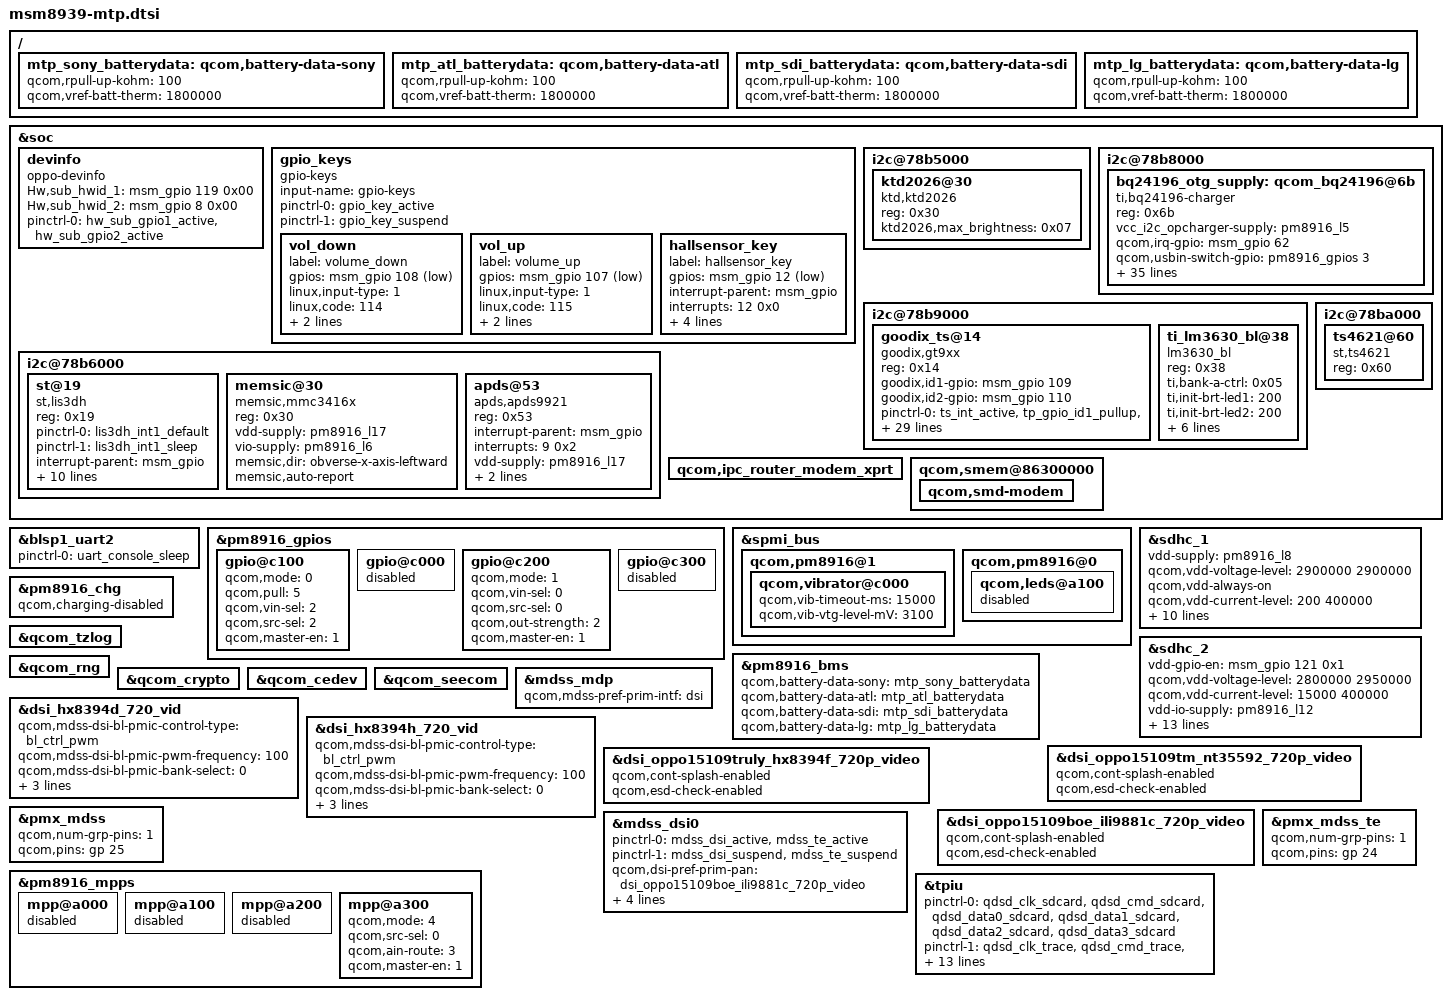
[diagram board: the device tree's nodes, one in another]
/* Copyright (c) 2014-2015, The Linux Foundation. All rights reserved.
 *
 * This program is free software; you can redistribute it and/or modify
 * it under the terms of the GNU General Public License version 2 and
 * only version 2 as published by the Free Software Foundation.
 *
 * This program is distributed in the hope that it will be useful,
 * but WITHOUT ANY WARRANTY; without even the implied warranty of
 * MERCHANTABILITY or FITNESS FOR A PARTICULAR PURPOSE.  See the
 * GNU General Public License for more details.
 */

#include "msm8939-audio-internal_codec.dtsi"
#include "msm8939-camera-sensor-mtp.dtsi"
#include "msm8939-common.dtsi"
#include "msm8939-pinctrl.dtsi"
#include "msm8939-regulator.dtsi"
#include "msm-pm8916.dtsi"
#include "dsi-panel-hx8394d-720p-video.dtsi"
#include "dsi-panel-hx8394h-720p-video.dtsi"
#include "dsi-panel-oppo15109tm-nt35592-720p-video.dtsi"
#include "dsi-panel-oppo15109truly-hx8394f-720p-video.dtsi"
#include "dsi-panel-oppo15109boe-ili9881c-720p-video.dtsi"

&soc {
	devinfo {
		compatible = "oppo-devinfo";
		Hw,sub_hwid_1 = <&msm_gpio 119 0x00>;
		Hw,sub_hwid_2 = <&msm_gpio 8 0x00>;
		pinctrl-names = "default";
		pinctrl-0 = <&hw_sub_gpio1_active &hw_sub_gpio2_active>;
	};

	gpio_keys {
		compatible = "gpio-keys";
		input-name = "gpio-keys";
		pinctrl-names = "tlmm_gpio_key_active", "tlmm_gpio_key_suspend";
		pinctrl-0 = <&gpio_key_active>;
		pinctrl-1 = <&gpio_key_suspend>;

		vol_down {
			label = "volume_down";
			gpios = <&msm_gpio 108 0x1>;
			linux,input-type = <1>;
			linux,code = <114>;
			gpio-key,wakeup;
			debounce-interval = <15>;
		};

		vol_up {
			label = "volume_up";
			gpios = <&msm_gpio 107 0x1>;
			linux,input-type = <1>;
			linux,code = <115>;
			gpio-key,wakeup;
			debounce-interval = <15>;
		};

		hallsensor_key {
			label = "hallsensor_key";
			gpios = <&msm_gpio 12 1>;
			interrupt-parent = <&msm_gpio>;
			interrupts = <12 0x0>;
			linux,input-type = <5>;
			linux,code = <0>;
			gpio-key,wakeup;
			debounce-interval = <150>;
		};
	};

	i2c@78b5000 { /* BLSP1 QUP1 */
		ktd2026@30 {
			status = "okay";
			compatible = "ktd,ktd2026";
			reg = <0x30>;
			ktd2026,max_brightness = <0x07>;
		};
	};

	i2c@78b6000 { /* BLSP1 QUP2 */
		st@19 { /* Accelerometer sensor */
			compatible = "st,lis3dh";
			reg = <0x19>;
			pinctrl-names = "lis3dh_default", "lis3dh_sleep";
			pinctrl-0 = <&lis3dh_int1_default>;
			pinctrl-1 = <&lis3dh_int1_sleep>;
			interrupt-parent = <&msm_gpio>;
			vdd-supply = <&pm8916_l17>;
			vddio-supply = <&pm8916_l6>;
			st,min-interval = <5>;
			st,init-interval = <200>;
			st,axis-map-x = <0>;
			st,axis-map-y = <1>;
			st,axis-map-z = <2>;
			st,g-range = <2>;
			st,negate-x;
			st,negate-z;
		};

		memsic@30 { /* Magnetic field sensor */
			compatible = "memsic,mmc3416x";
			reg = <0x30>;
			vdd-supply = <&pm8916_l17>;
			vio-supply = <&pm8916_l6>;
			memsic,dir = "obverse-x-axis-leftward";
			memsic,auto-report;
		};

		apds@53 { /* Ambient light and proximity sensor */
			compatible = "apds,apds9921";
			reg = <0x53>;
			interrupt-parent = <&msm_gpio>;
			interrupts = <9 0x2>;
			vdd-supply = <&pm8916_l17>;
			vio-supply = <&pm8916_l6>;
			apds,irq-gpio = <&msm_gpio 9 0x02>;
		};
	};

	i2c@78b8000 { /* BLSP1 QUP4 */
		bq24196_otg_supply: qcom_bq24196@6b {
			compatible = "ti,bq24196-charger";
			reg = <0x6b>;
			vcc_i2c_opcharger-supply = <&pm8916_l5>;

			qcom,irq-gpio = <&msm_gpio 62 0x00>;
			qcom,usbin-switch-gpio = <&pm8916_gpios 3 0>;

			qcom,disable-apsd;
			qcom,using-pmic-therm;
			qcom,charger-inhibit-disabled;
			qcom,bms-psy-name = "bms";
			qcom,chg-vadc = <&pm8916_vadc>;
			qcom,chg-adc_tm = <&pm8916_adc_tm>;

			qcom,iterm-ma = <130>;
			qcom,recharge-mv = <200>;
			qcom,fast-charger-project-sign= <0>;
			qcom,fastchg-current-max-ma = <1500>;
			qcom,input-current-max-ma = <1500>;
			qcom,float-voltage-mv = <4320>;

			qcom,hot_bat_decidegc = <530>;
			qcom,temp_hot_vfloat_mv = <4100>;
			qcom,temp_hot_fastchg_current_ma = <535>;

			qcom,warm_bat_decidegc = <450>;
			qcom,temp_warm_vfloat_mv = <4320>;
			qcom,temp_warm_fastchg_current_ma = <1420>;

			qcom,pre_normal_bat_decidegc = <220>;
			qcom,temp_pre_normal_vfloat_mv = <4320>;
			qcom,temp_pre_normal_fastchg_current_ma = <1120>;

			qcom,pre_cool_bat_decidegc = <120>;
			qcom,temp_pre_cool_vfloat_mv = <4320>;
			qcom,temp_pre_cool_fastchg_current_ma = <535>;

			qcom,pre_cool1_bat_decidegc = <50>;
			qcom,temp_pre_cool1_vfloat_mv = <4320>;
			qcom,temp_pre_cool1_fastchg_current_ma = <300>;

			qcom,cool_bat_decidegc = <0>;
			qcom,temp_cool_vfloat_mv = <4000>;
			qcom,temp_cool_fastchg_current_ma = <256>;

			qcom,cold_bat_decidegc = <30>;
			qcom,bat_present_decidegc = <200>;
			qcom,non_standard_vfloat_mv = <4000>;
			qcom,non_standard_fastchg_current_ma = <512>;

			regulator-name = "bq24196_otg_vreg";
		};
	};

	i2c@78b9000 { /* BLSP1 QUP5 */
		goodix_ts@14 {
			compatible = "goodix,gt9xx";
			reg = <0x14>;

			goodix,id1-gpio = <&msm_gpio 109 0x00>;
			goodix,id2-gpio = <&msm_gpio 110 0x00>;

			pinctrl-names = "default", "tp_id_pull_up", "tp_id_pull_down";
			pinctrl-0 = <&ts_int_active &tp_gpio_id1_pullup &tp_gpio_id2_pullup>;
			pinctrl-1 = <&tp_gpio_id1_pullup &tp_gpio_id2_pullup>;
			pinctrl-2 = <&tp_gpio_id1_pulldown &tp_gpio_id2_pulldown>;
			vdd-supply = <&pm8916_l17>;
			vcc_i2c-supply = <&pm8916_l6>;
			interrupt-parent = <&msm_gpio>;
			interrupts = <13 0x2008>;
			reset-gpios = <&msm_gpio 21 0x00>;
			interrupt-gpios = <&msm_gpio 13 0x00>;
			goodix,panel-coords = <0 0 720 1280>;
			goodix,display-coords = <0 0 720 1280>;
			goodix,button-map= <90 100 1350>;
			goodix,product-id = "915";
			goodix,dbl_clk_wakeup;
			goodix,cfg-data0 = [
				42 D0 02 00 05 05 05 41 01 C5
				28 09 55 3C 03 05 00 00 EF 03
				00 00 00 14 17 19 14 8B 2A 0C
				32 35 0C 08 00 00 00 02 33 1D
				56 05 00 00 00 00 00 00 00 00
				1C 1E 50 94 D5 02 07 00 00 04
				A8 21 00 93 28 00 81 31 00 74
				3B 00 68 48 00 68 10 30 50 00
				F5 4A 3A FF FF 27 00 00 00 00
				00 00 00 00 00 00 00 00 00 00
				00 00 00 00 66 00 04 19 01 11
				43 00 02 04 06 08 0A 0C 0E 10
				12 14 16 18 FF FF 00 00 00 00
				00 00 00 00 00 00 00 00 00 00
				00 00 24 18 22 1C 21 1D 20 1E
				16 1F 12 08 06 10 04 0F 02 0C
				00 0A 13 FF FF FF FF FF 00 00
				00 FF FF FF FF FF FF 11 11 11
				11 FF FF FF 6D 01];
			goodix,cfg-data1 = [
				42 D0 02 00 05 05 05 41 01 C5
				1E 09 50 3C 03 05 00 00 EF 03
				00 00 00 00 00 00 00 8B 0A 0C
				30 33 0C 08 00 00 00 02 33 1D
				56 01 00 00 00 00 00 00 00 00
				1B 19 50 94 D5 02 07 00 00 04
				CC 1C 00 A7 23 00 87 2D 00 71
				38 00 5E 47 00 5E 10 30 58 00
				57 45 35 FF F0 17 00 00 00 00
				00 00 00 00 00 00 00 00 00 00
				00 00 00 00 66 00 04 19 01 11
				44 3C 02 04 06 08 0A 0C 0E 10
				12 14 16 18 FF FF 00 00 00 00
				00 00 00 00 00 00 00 00 00 00
				00 00 12 02 10 04 0F 06 0C 08
				00 0A 24 1E 1D 22 1C 21 18 20
				16 1F 26 FF FF FF FF FF 00 00
				00 FF FF FF FF FF FF FF FF FF
				FF FF FF FF A4 01];
			goodix,cfg-data2 = [
				41 D0 02 00 05 05 05 41 01 08
				28 08 50 32 03 05 00 00 FF 7F
				00 00 08 00 00 00 00 8B 2A 0C
				32 34 B9 08 00 00 00 9A 33 1D
				3C 01 00 00 00 00 00 00 00 00
				1A 1A 5A 94 D5 02 00 00 00 04
				B8 1D 00 97 26 00 82 30 00 71
				3E 00 63 50 00 63 10 30 50 00
				F5 4A 3A FF FF 27 00 00 00 00
				00 00 00 00 00 00 00 00 00 00
				00 00 00 00 00 00 05 0F 01 11
				50 50 02 04 06 08 0A 0C 0E 10
				12 14 16 18 FF FF 00 00 00 00
				00 00 00 00 00 00 00 00 00 00
				00 00 24 18 22 1C 21 1D 20 1E
				16 1F 12 08 06 10 04 0F 02 0C
				00 0A 13 FF FF FF FF FF 00 00
				00 FF FF FF FF FF FF FF FF FF
				FF FF FF FF 2A 01];
			goodix,cfg-data3 = [
				41 D0 02 00 05 05 05 41 01 08
				28 08 50 32 03 05 00 00 FF 7F
				00 00 08 00 00 00 00 8B 2A 0C
				32 34 B9 08 00 00 00 9A 33 1D
				3C 01 00 00 00 00 00 00 00 00
				1A 1A 5A 94 D5 02 00 00 00 04
				B8 1D 00 97 26 00 82 30 00 71
				3E 00 63 50 00 63 10 30 50 00
				F5 4A 3A FF FF 27 00 00 00 00
				00 00 00 00 00 00 00 00 00 00
				00 00 00 00 00 00 05 0F 01 11
				50 50 02 04 06 08 0A 0C 0E 10
				12 14 16 18 FF FF 00 00 00 00
				00 00 00 00 00 00 00 00 00 00
				00 00 24 18 22 1C 21 1D 20 1E
				16 1F 12 08 06 10 04 0F 02 0C
				00 0A 13 FF FF FF FF FF 00 00
				00 FF FF FF FF FF FF FF FF FF
				FF FF FF FF 2A 01];
			goodix,cfg-data4 = [
				41 D0 02 00 05 05 05 41 01 08
				28 08 50 32 03 05 00 00 FF 7F
				00 00 08 00 00 00 00 8B 2A 0C
				32 34 B9 08 00 00 00 9A 33 1D
				3C 01 00 00 00 00 00 00 00 00
				1A 1A 5A 94 D5 02 00 00 00 04
				B8 1D 00 97 26 00 82 30 00 71
				3E 00 63 50 00 63 10 30 50 00
				F5 4A 3A FF FF 27 00 00 00 00
				00 00 00 00 00 00 00 00 00 00
				00 00 00 00 00 00 05 0F 01 11
				50 50 02 04 06 08 0A 0C 0E 10
				12 14 16 18 FF FF 00 00 00 00
				00 00 00 00 00 00 00 00 00 00
				00 00 24 18 22 1C 21 1D 20 1E
				16 1F 12 08 06 10 04 0F 02 0C
				00 0A 13 FF FF FF FF FF 00 00
				00 FF FF FF FF FF FF FF FF FF
				FF FF FF FF 2A 01];
			goodix,cfg-data5 = [
				41 D0 02 00 05 05 05 41 01 08
				28 08 50 32 03 05 00 00 FF 7F
				00 00 08 00 00 00 00 8B 2A 0C
				32 34 B9 08 00 00 00 9A 33 1D
				3C 01 00 00 00 00 00 00 00 00
				1A 1A 5A 94 D5 02 00 00 00 04
				B8 1D 00 97 26 00 82 30 00 71
				3E 00 63 50 00 63 10 30 50 00
				F5 4A 3A FF FF 27 00 00 00 00
				00 00 00 00 00 00 00 00 00 00
				00 00 00 00 00 00 05 0F 01 11
				50 50 02 04 06 08 0A 0C 0E 10
				12 14 16 18 FF FF 00 00 00 00
				00 00 00 00 00 00 00 00 00 00
				00 00 24 18 22 1C 21 1D 20 1E
				16 1F 12 08 06 10 04 0F 02 0C
				00 0A 13 FF FF FF FF FF 00 00
				00 FF FF FF FF FF FF FF FF FF
				FF FF FF FF 2A 01];
			goodix,fw_name = "gtp_fw.bin";
		};

		ti_lm3630_bl@38 {
			compatible = "lm3630_bl";
			reg = <0x38>;
			ti,bank-a-ctrl = <0x05>;
			ti,init-brt-led1 = <200>;
			ti,init-brt-led2 = <200>;
			ti,max-brt-led1 = <255>;
			ti,max-brt-led2 = <255>;
			ti,pwm-active = <0>;
			ti,pwm-ctrl = <0>;
			ti,pwm-period = <255>;
			ti,bl-enable-gpio = <&msm_gpio 115 0x00>;
		};
	};

	i2c@78ba000 { /* BLSP1 QUP6 */
		ts4621@60 {
			status = "okay";
			compatible = "st,ts4621";
			reg = <0x60>;
		};
	};

	qcom,ipc_router_modem_xprt {
		/delete-property/ qcom,disable-pil-loading;
	};

	qcom,smem@86300000 {
		qcom,smd-modem {
			/delete-property/ qcom,not-loadable;
		};
	};
};

&blsp1_uart2 {
	status = "ok";
	pinctrl-names = "default";
	pinctrl-0 = <&uart_console_sleep>;
};

&pm8916_gpios {
	gpio@c100 { /* GPIO 2 */
		/* NFC_CLK_REQ */
		qcom,mode = <0>; /* QPNP_PIN_MODE_DIG_IN */
		qcom,pull = <5>; /* QPNP_PIN_PULL_NO */
		qcom,vin-sel = <2>; /* QPNP_PIN_VIN2 */
		qcom,src-sel = <2>; /* QPNP_PIN_SEL_FUNC_1 */
		qcom,master-en = <1>;
	};
};

&spmi_bus {
	qcom,pm8916@1 {
		qcom,vibrator@c000 {
			status = "okay";
			qcom,vib-timeout-ms = <15000>;
			qcom,vib-vtg-level-mV = <3100>;
		};
	};

	qcom,pm8916@0 {
		qcom,leds@a100 {
			status = "disabled";
		};
	};
};

&sdhc_1 {
	vdd-supply = <&pm8916_l8>;
	qcom,vdd-voltage-level = <2900000 2900000>;
	qcom,vdd-always-on;
	qcom,vdd-current-level = <200 400000>;

	vdd-io-supply = <&pm8916_l5>;
	qcom,vdd-io-always-on;
	qcom,vdd-io-lpm-sup;
	qcom,vdd-io-voltage-level = <1800000 1800000>;
	qcom,vdd-io-current-level = <200 60000>;

	pinctrl-names = "active", "sleep";
	pinctrl-0 = <&sdc1_clk_on &sdc1_cmd_on &sdc1_data_on>;
	pinctrl-1 = <&sdc1_clk_off &sdc1_cmd_off &sdc1_data_off>;

	qcom,nonremovable;

	status = "ok";
};

&sdhc_2 {
	vdd-gpio-en = <&msm_gpio 121 0x1>;
	qcom,vdd-voltage-level = <2800000 2950000>;
	qcom,vdd-current-level = <15000 400000>;

	vdd-io-supply = <&pm8916_l12>;
	qcom,vdd-io-voltage-level = <1800000 2950000>;
	qcom,vdd-io-current-level = <200 50000>;

	pinctrl-names = "default", "active", "sleep";
	pinctrl-0 = <&sdc2_cd_on &sim1_cd_on &sim2_cd_on>;
	pinctrl-1 = <&sdc2_clk_on &sdc2_cmd_on &sdc2_data_on &sdc2_cd_on>;
	pinctrl-2 = <&sdc2_clk_off &sdc2_cmd_off &sdc2_data_off &sdc2_cd_off>;

	#address-cells = <0>;
	interrupt-parent = <&sdhc_2>;
	interrupts = <0 1 2>;
	#interrupt-cells = <1>;
	interrupt-map-mask = <0xffffffff>;
	interrupt-map = <0 &intc 0 125 0
			1 &intc 0 221 0
			2 &msm_gpio 38 0>;
	interrupt-names = "hc_irq", "pwr_irq", "status_irq";
	cd-gpios = <&msm_gpio 38 0x0>;

	status = "ok";
};

&pm8916_chg {
	status = "ok";
	qcom,charging-disabled;
};

/ {
	mtp_sony_batterydata: qcom,battery-data-sony {
		qcom,rpull-up-kohm = <100>;
		qcom,vref-batt-therm = <1800000>;
		#include "batterydata-oppo-sony-4v35-2420mah.dtsi"
	};

	mtp_atl_batterydata: qcom,battery-data-atl {
		qcom,rpull-up-kohm = <100>;
		qcom,vref-batt-therm = <1800000>;
		#include "batterydata-oppo-atl-4v35-2420mah.dtsi"
	};

	mtp_sdi_batterydata: qcom,battery-data-sdi {
		qcom,rpull-up-kohm = <100>;
		qcom,vref-batt-therm = <1800000>;
		#include "batterydata-oppo-sdi-4v35-2420mah.dtsi"
	};

	mtp_lg_batterydata: qcom,battery-data-lg {
		qcom,rpull-up-kohm = <100>;
		qcom,vref-batt-therm = <1800000>;
		#include "batterydata-oppo-lg-4v35-2420mah.dtsi"
	};
};

&pm8916_bms {
	status = "ok";
	qcom,battery-data-sony = <&mtp_sony_batterydata>;
	qcom,battery-data-atl = <&mtp_atl_batterydata>;
	qcom,battery-data-sdi = <&mtp_sdi_batterydata>;
	qcom,battery-data-lg = <&mtp_lg_batterydata>;
};

&qcom_tzlog {
	status = "okay";
};

&qcom_rng {
	status = "okay";
};

&qcom_crypto {
	status = "okay";
};

&qcom_cedev {
	status = "okay";
};

&qcom_seecom {
	status = "okay";
};

&mdss_mdp {
	qcom,mdss-pref-prim-intf = "dsi";
};

&dsi_hx8394d_720_vid {
	qcom,mdss-dsi-bl-pmic-control-type = "bl_ctrl_pwm";
	qcom,mdss-dsi-bl-pmic-pwm-frequency = <100>;
	qcom,mdss-dsi-bl-pmic-bank-select = <0>;
	qcom,mdss-dsi-pwm-gpio = <&pm8916_mpps 4 0>;
	qcom,cont-splash-enabled;
	qcom,esd-check-enabled;
};

&dsi_hx8394h_720_vid {
	qcom,mdss-dsi-bl-pmic-control-type = "bl_ctrl_pwm";
	qcom,mdss-dsi-bl-pmic-pwm-frequency = <100>;
	qcom,mdss-dsi-bl-pmic-bank-select = <0>;
	qcom,mdss-dsi-pwm-gpio = <&pm8916_mpps 4 0>;
	qcom,cont-splash-enabled;
	qcom,esd-check-enabled;
};

&dsi_oppo15109tm_nt35592_720p_video {
	qcom,cont-splash-enabled;
	qcom,esd-check-enabled;
};

&dsi_oppo15109truly_hx8394f_720p_video {
	qcom,cont-splash-enabled;
	qcom,esd-check-enabled;
};

&dsi_oppo15109boe_ili9881c_720p_video {
	qcom,cont-splash-enabled;
	qcom,esd-check-enabled;
};

&pmx_mdss {
	qcom,num-grp-pins = <1>;
	qcom,pins = <&gp 25>;
};

&pmx_mdss_te {
	qcom,num-grp-pins = <1>;
	qcom,pins = <&gp 24>;
};

&mdss_dsi0 {
	pinctrl-names = "mdss_default", "mdss_sleep";
	pinctrl-0 = <&mdss_dsi_active &mdss_te_active>;
	pinctrl-1 = <&mdss_dsi_suspend &mdss_te_suspend>;

	qcom,dsi-pref-prim-pan = <&dsi_oppo15109boe_ili9881c_720p_video>;

	qcom,platform-enable-gpio = <&msm_gpio 114 0>;
	qcom,platform-reset-gpio = <&msm_gpio 25 0>;
	qcom,platform-bklight-en-gpio = <&msm_gpio 113 0>;
	qcom,platform-lcd-enable-gpio = <&msm_gpio 120 0>;
};

&pm8916_mpps {
	mpp@a000 { /* MPP 1 */
		/* VDD_PX */
		status = "disabled";
	};

	mpp@a100 { /* MPP 2 */
		/* HR LED */
		status = "disabled";
	};

	mpp@a200 { /* MPP 3 */
		/* VREF DAC */
		status = "disabled";
	};

	mpp@a300 { /* MPP 4 */
		/* ADC */
		qcom,mode = <4>; // QPNP_PIN_MODE_AIN
		qcom,src-sel = <0>; // QPNP_PIN_SEL_FUNC_CONSTANT
		qcom,ain-route = <3>; // QPNP_PIN_AIN_AMUX_CH8
		qcom,master-en = <1>; // Enable features
	};
};

&pm8916_gpios {
	gpio@c000 { /* GPIO 1 */
		/* Battery UICC Alarm */
		status = "disabled";
	};

	gpio@c100 { /* GPIO 2 */
		/* NFC_CLK_REQ */
		qcom,mode = <0>; /* QPNP_PIN_MODE_DIG_IN */
		qcom,pull = <5>; /* QPNP_PIN_PULL_NO */
		qcom,vin-sel = <2>; /* QPNP_PIN_VIN2 */
		qcom,src-sel = <2>; /* QPNP_PIN_SEL_FUNC_1 */
		qcom,master-en = <1>;
	};

	gpio@c200 { /* GPIO 3 */
		/* External regulator control for WTR */
		status = "ok";
		qcom,mode = <1>; /* QPNP_PIN_MODE_DIG_OUT */
		qcom,vin-sel = <0>; /* VPH_PWR */
		qcom,src-sel = <0>; /* QPNP_PIN_SEL_FUNC_CONSTANT */
		qcom,out-strength = <2>; /* QPNP_PIN_OUT_STRENGTH_MED */
		qcom,master-en = <1>;
	};

	gpio@c300 { /* GPIO 4 */
		/* External regulator control for APC */
		status = "disabled";
	};
};

/* CoreSight */
&tpiu {
	pinctrl-names = "sdcard", "trace", "swduart",
			"swdtrc", "jtag", "spmi";
	/* NIDnT */
	pinctrl-0 = <&qdsd_clk_sdcard &qdsd_cmd_sdcard
		     &qdsd_data0_sdcard &qdsd_data1_sdcard
		     &qdsd_data2_sdcard &qdsd_data3_sdcard>;
	pinctrl-1 = <&qdsd_clk_trace &qdsd_cmd_trace
		     &qdsd_data0_trace &qdsd_data1_trace
		     &qdsd_data2_trace &qdsd_data3_trace>;
	pinctrl-2 = <&qdsd_cmd_swduart &qdsd_data0_swduart
		     &qdsd_data1_swduart &qdsd_data2_swduart
		     &qdsd_data3_swduart>;
	pinctrl-3 = <&qdsd_clk_swdtrc &qdsd_cmd_swdtrc
		     &qdsd_data0_swdtrc &qdsd_data1_swdtrc
		     &qdsd_data2_swdtrc &qdsd_data3_swdtrc>;
	pinctrl-4 = <&qdsd_cmd_jtag &qdsd_data0_jtag
		     &qdsd_data1_jtag &qdsd_data2_jtag
		     &qdsd_data3_jtag>;
	pinctrl-5 = <&qdsd_clk_spmi &qdsd_cmd_spmi
		     &qdsd_data0_spmi &qdsd_data3_spmi>;
};
